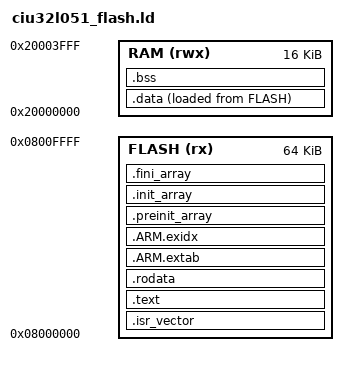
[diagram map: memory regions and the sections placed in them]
/*
 * ciu32l051_flash.ld - CIU32L051x8 链接脚本
 *
 * 存储映射依据：
 *   数据手册 DS1007 CIU32L051x8：64KB Flash，16KB SRAM；
 *   器件头文件 ciu32l051.h：FLASH_MEM_BASE = 0x08000000，SRAM_BASE = 0x20000000。
 * 本工程不使用 Bootloader 跳转，代码从 0x08000000 开始；
 * 若改为 IAP 应用，ORIGIN 偏移、SCB->VTOR 与烧写起始地址必须同时改。
 */

ENTRY(Reset_Handler)

_Min_Stack_Size = 0x00000400;   /* 1KB，与厂商启动文件 Stack_Size 一致 */

MEMORY
{
    FLASH (rx)  : ORIGIN = 0x08000000, LENGTH = 64K
    RAM   (rwx) : ORIGIN = 0x20000000, LENGTH = 16K
}

_estack = ORIGIN(RAM) + LENGTH(RAM);

SECTIONS
{
    .isr_vector :
    {
        . = ALIGN(128);
        KEEP(*(.isr_vector))
        . = ALIGN(4);
    } > FLASH

    .text :
    {
        . = ALIGN(4);
        *(.text)
        *(.text*)
        *(.glue_7)
        *(.glue_7t)
        *(.eh_frame)
        KEEP(*(.init))
        KEEP(*(.fini))
        . = ALIGN(4);
    } > FLASH

    .rodata :
    {
        . = ALIGN(4);
        *(.rodata)
        *(.rodata*)
        . = ALIGN(4);
    } > FLASH

    .ARM.extab :
    {
        *(.ARM.extab* .gnu.linkonce.armextab.*)
    } > FLASH

    .ARM.exidx :
    {
        __exidx_start = .;
        *(.ARM.exidx*)
        __exidx_end = .;
    } > FLASH

    .preinit_array :
    {
        . = ALIGN(4);
        PROVIDE_HIDDEN(__preinit_array_start = .);
        KEEP(*(.preinit_array*))
        PROVIDE_HIDDEN(__preinit_array_end = .);
        . = ALIGN(4);
    } > FLASH

    .init_array :
    {
        . = ALIGN(4);
        PROVIDE_HIDDEN(__init_array_start = .);
        KEEP(*(SORT(.init_array.*)))
        KEEP(*(.init_array*))
        PROVIDE_HIDDEN(__init_array_end = .);
        . = ALIGN(4);
    } > FLASH

    .fini_array :
    {
        . = ALIGN(4);
        PROVIDE_HIDDEN(__fini_array_start = .);
        KEEP(*(SORT(.fini_array.*)))
        KEEP(*(.fini_array*))
        PROVIDE_HIDDEN(__fini_array_end = .);
        . = ALIGN(4);
    } > FLASH

    _sidata = LOADADDR(.data);

    .data :
    {
        . = ALIGN(4);
        _sdata = .;
        *(.data)
        *(.data*)
        . = ALIGN(4);
        _edata = .;
    } > RAM AT > FLASH

    .bss (NOLOAD) :
    {
        . = ALIGN(4);
        _sbss = .;
        __bss_start__ = _sbss;
        *(.bss)
        *(.bss*)
        *(COMMON)
        . = ALIGN(4);
        _ebss = .;
        __bss_end__ = _ebss;
    } > RAM

    . = ALIGN(4);
    _end = .;
    PROVIDE(end = .);

    /* 栈从 _estack 向下生长，bss 末尾到 _estack 之间必须留出 Min_Stack_Size */
    ASSERT(_ebss + _Min_Stack_Size <= _estack, "Error: SRAM 不足，栈空间被 .bss 挤占")
}
